# ATmega328PB device description
Architecture: AVR8; Family: megaAVR
Registers are 8-bit, access not given, no defined reset value unless marked. A register's access mark holds for its fields unless they carry their own. Offsets are from the block's base; [hi:lo] are bit positions.

## TWI0 — Two Wire Serial Interface
Instances: TWI0 0x00
0xB8 TWBR0 — TWI Bit Rate register
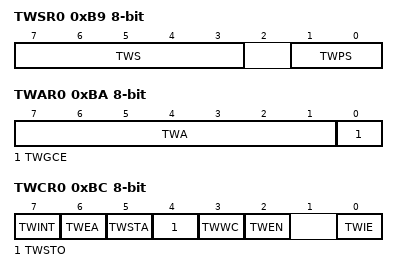
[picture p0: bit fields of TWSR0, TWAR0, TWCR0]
0xB9 TWSR0 — TWI Status Register
  [7:3] TWS (bit 3 of the value upward) — TWI Status
  [1:0] TWPS — TWI Prescaler
    0=1; 1=4; 2=16; 3=64
0xBA TWAR0 — TWI (Slave) Address register
  [7:1] TWA — TWI (Slave) Address register Bits
  [0] TWGCE — TWI General Call Recognition Enable Bit
0xBB TWDR0 — TWI Data register
0xBC TWCR0 — TWI Control Register
  [7] TWINT — TWI Interrupt Flag
  [6] TWEA — TWI Enable Acknowledge Bit
  [5] TWSTA — TWI Start Condition Bit
  [4] TWSTO — TWI Stop Condition Bit
  [3] TWWC — TWI Write Collision Flag
  [2] TWEN — TWI Enable Bit
  [0] TWIE — TWI Interrupt Enable
0xBD TWAMR0 — TWI (Slave) Address Mask Register
  [7:1] TWAM

## TWI1 — Two Wire Serial Interface
Instances: TWI1 0x00
0xD8 TWBR1 — TWI Bit Rate register
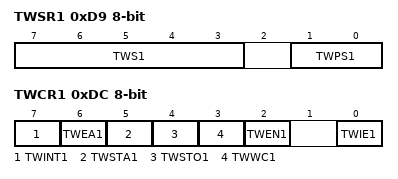
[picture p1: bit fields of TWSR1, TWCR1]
0xD9 TWSR1 — TWI Status Register
  [7:3] TWS1 (bit 3 of the value upward) — TWI Status
  [1:0] TWPS1 — TWI Prescaler
    0=1; 1=4; 2=16; 3=64
0xDA TWAR1 — TWI (Slave) Address register
0xDB TWDR1 — TWI Data register
0xDC TWCR1 — TWI Control Register
  [7] TWINT1 — TWI Interrupt Flag
  [6] TWEA1 — TWI Enable Acknowledge Bit
  [5] TWSTA1 — TWI Start Condition Bit
  [4] TWSTO1 — TWI Stop Condition Bit
  [3] TWWC1 — TWI Write Collision Flag
  [2] TWEN1 — TWI Enable Bit
  [0] TWIE1 — TWI Interrupt Enable
0xDD TWAMR1 — TWI (Slave) Address Mask Register
  [7:1] TWAM1

## TC1 (TC16 module)
Instances: TC1 0x00
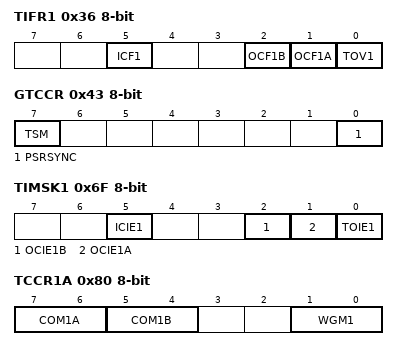
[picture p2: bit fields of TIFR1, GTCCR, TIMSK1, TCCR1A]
0x36 TIFR1 — Timer/Counter1 Interrupt Flag register
  [5] ICF1 — Timer/Counter1 Input Capture Flag
  [2] OCF1B — Timer/Counter1 Output Compare B Match Flag
  [1] OCF1A — Timer/Counter1 Output Compare A Match Flag
  [0] TOV1 — Timer/Counter1 Overflow Flag
0x43 GTCCR — General Timer/Counter Control Register
  [7] TSM — Timer/Counter Synchronization Mode
  [0] PSRSYNC — Prescaler Reset Timer/Counter1 and Timer/Counter0
0x6F TIMSK1 — Timer/Counter1 Interrupt Mask Register
  [5] ICIE1 — Timer/Counter1 Input Capture Interrupt Enable
  [2] OCIE1B — Timer/Counter1 Output Compare B Match Interrupt Enable
  [1] OCIE1A — Timer/Counter1 Output Compare A Match Interrupt Enable
  [0] TOIE1 — Timer/Counter1 Overflow Interrupt Enable
0x80 TCCR1A — Timer/Counter1 Control Register A
  [7:6] COM1A — Compare Output Mode 1A bits
  [5:4] COM1B — Compare Output Mode 1B bits
  [1:0] WGM1 — Waveform Generation Mode
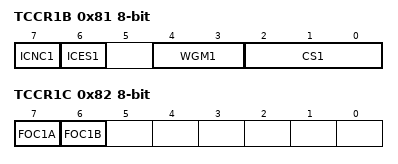
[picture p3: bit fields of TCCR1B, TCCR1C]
0x81 TCCR1B — Timer/Counter1 Control Register B
  [7] ICNC1 — Input Capture Noise Canceler
  [6] ICES1 — Input Capture Edge Select
  [4:3] WGM1 (bit 2 of the value upward) — Waveform Generation Mode
  [2:0] CS1 — Clock Select bits
    0=NO_CLOCK_SOURCE_STOPPED; 1=RUNNING_NO_PRESCALING; 2=RUNNING_CLK_8; 3=RUNNING_CLK_64; 4=RUNNING_CLK_256; 5=RUNNING_CLK_1024; 6=RUNNING_EXTCLK_TN_FALLING_EDGE; 7=RUNNING_EXTCLK_TN_RISING_EDGE
0x82 TCCR1C — Timer/Counter1 Control Register C
  [7] FOC1A — Force Output Compare for Channel A
  [6] FOC1B — Force Output Compare for Channel B
0x84 TCNT1 16-bit — Timer/Counter1 Bytes
0x86 ICR1 16-bit — Timer/Counter1 Input Capture Register Bytes
0x88 OCR1A 16-bit — Timer/Counter1 Output Compare Register Bytes
0x8A OCR1B 16-bit — Timer/Counter1 Output Compare Register Bytes

## TC3 (TC16 module)
Instances: TC3 0x00
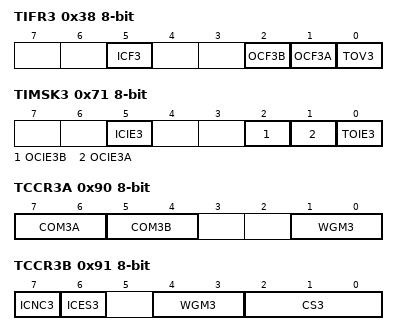
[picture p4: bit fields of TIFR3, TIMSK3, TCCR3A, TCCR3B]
0x38 TIFR3 — Timer/Counter3 Interrupt Flag register
  [5] ICF3 — Timer/Counter3 Input Capture Flag
  [2] OCF3B — Timer/Counter3 Output Compare B Match Flag
  [1] OCF3A — Timer/Counter3 Output Compare A Match Flag
  [0] TOV3 — Timer/Counter3 Overflow Flag
0x71 TIMSK3 — Timer/Counter3 Interrupt Mask Register
  [5] ICIE3 — Timer/Counter3 Input Capture Interrupt Enable
  [2] OCIE3B — Timer/Counter3 Output Compare B Match Interrupt Enable
  [1] OCIE3A — Timer/Counter3 Output Compare A Match Interrupt Enable
  [0] TOIE3 — Timer/Counter3 Overflow Interrupt Enable
0x90 TCCR3A — Timer/Counter3 Control Register A
  [7:6] COM3A — Compare Output Mode 3A bits
  [5:4] COM3B — Compare Output Mode 3B bits
  [1:0] WGM3 — Waveform Generation Mode
0x91 TCCR3B — Timer/Counter3 Control Register B
  [7] ICNC3 — Input Capture Noise Canceler
  [6] ICES3 — Input Capture Edge Select
  [4:3] WGM3 (bit 2 of the value upward) — Waveform Generation Mode
  [2:0] CS3 — Clock Select bits
    0=NO_CLOCK_SOURCE_STOPPED; 1=RUNNING_NO_PRESCALING; 2=RUNNING_CLK_8; 3=RUNNING_CLK_64; 4=RUNNING_CLK_256; 5=RUNNING_CLK_1024; 6=RUNNING_EXTCLK_TN_FALLING_EDGE; 7=RUNNING_EXTCLK_TN_RISING_EDGE
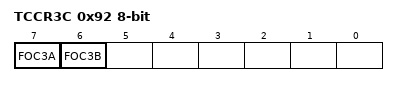
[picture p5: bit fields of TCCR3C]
0x92 TCCR3C — Timer/Counter3 Control Register C
  [7] FOC3A — Force Output Compare for Channel A
  [6] FOC3B — Force Output Compare for Channel B
0x94 TCNT3 16-bit — Timer/Counter3 Bytes
0x96 ICR3 16-bit — Timer/Counter3 Input Capture Register Bytes
0x98 OCR3A 16-bit — Timer/Counter3 Output Compare Register Bytes
0x9A OCR3B 16-bit — Timer/Counter3 Output Compare Register Bytes
